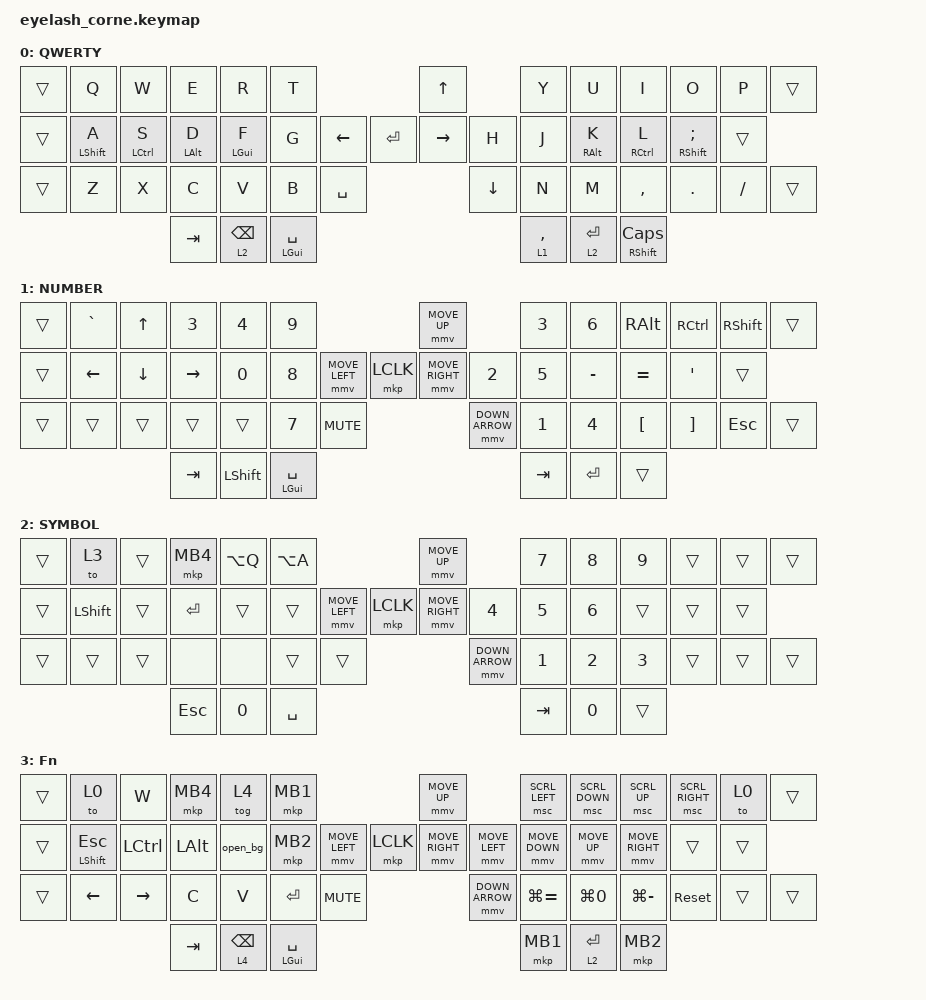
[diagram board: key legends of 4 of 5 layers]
// Copyright (c) 2022 The ZMK Contributors
// SPDX-License-Identifier: MIT

#define ZMK_POINTING_DEFAULT_MOVE_VAL 2500
#define ZMK_POINTING_DEFAULT_SCRL_VAL 20

#include <input/processors.dtsi>
#include <zephyr/dt-bindings/input/input-event-codes.h>
#include <behaviors.dtsi>
#include <dt-bindings/zmk/keys.h>
#include <dt-bindings/zmk/pointing.h>
#include <dt-bindings/zmk/rgb.h>

/* 挂载到 &mmv_input_listener：在 4 号图层激活时强制将 XY 位移转化为滚轮信号 */
&mmv_input_listener {
    input-processors = <&zip_xy_scaler 1 1>;

    scroll_mode {
        layers = <4>;
        input-processors = <&zip_xy_to_scroll_mapper>, <&zip_scroll_scaler 1 1>;
    };
};

&msc_input_listener { input-processors = <&zip_scroll_scaler 1 1>; };

&msc {
    acceleration-exponent = <0>;
    time-to-max-speed-ms = <0>;
    delay-ms = <0>;
};

&mmv {
    acceleration-exponent = <1>;
    time-to-max-speed-ms = <200>;
    delay-ms = <0>;
};

&soft_off { hold-time-ms = <2000>; };

/ {
    macros {
        open_bg: open_bg {
            compatible = "zmk,behavior-macro";
            #binding-cells = <0>;
            bindings =
                <&macro_press>,
                <&kp LGUI>,
                <&macro_tap>,
                <&mkp LCLK>,
                <&macro_release>,
                <&kp LGUI>;
        };
    };

    behaviors {
        td0: td0 {
            compatible = "zmk,behavior-tap-dance";
            display-name = "Shift/Caps Lock Tap Dance";
            #binding-cells = <0>;
            bindings = <&kp LEFT_SHIFT>, <&kp CAPS>;
        };

        hm: homerow_mods {
            compatible = "zmk,behavior-hold-tap";
            #binding-cells = <2>;
            tapping-term-ms = <200>;
            quick-tap-ms = <175>;
            require-prior-idle-ms = <150>;
            flavor = "balanced";
            bindings = <&kp>, <&kp>;
        };
    };

    rgb_encoder: rgb_encoder {
        compatible = "zmk,behavior-sensor-rotate";
        #sensor-binding-cells = <0>;
        bindings = <&rgb_ug RGB_BRI>, <&rgb_ug RGB_BRD>;
    };

    scroll_encoder: scroll_encoder {
        compatible = "zmk,behavior-sensor-rotate";
        #sensor-binding-cells = <0>;
        bindings = <&msc SCRL_DOWN>, <&msc SCRL_UP>;

        tap-ms = <20>;
    };

    combos {
        compatible = "zmk,combos";

        rt {
            bindings = <&kp LEFT_PARENTHESIS>;
            key-positions = <4 5>;
        };

        yu {
            bindings = <&kp RIGHT_PARENTHESIS>;
            key-positions = <7 8>;
        };

        vb {
            bindings = <&kp LS(APOSTROPHE)>;
            key-positions = <32 33>;
        };

        nm {
            bindings = <&kp APOSTROPHE>;
            key-positions = <36 37>;
        };

        qw {
            bindings = <&kp ESC>;
            key-positions = <1 2>;
        };
    };

    keymap {
        compatible = "zmk,keymap";

        default_layer {
            display-name = "QWERTY";
            bindings = <
&trans  &kp Q              &kp W               &kp E               &kp R            &kp T                                                          &kp UP                &kp Y        &kp U        &kp I                 &kp O                &kp P                      &trans
&trans  &hm LEFT_SHIFT A  &hm LEFT_CONTROL S  &hm LEFT_ALT D      &hm LEFT_GUI F   &kp G                                               &kp LEFT  &kp ENTER  &kp RIGHT  &kp H        &kp J        &hm RIGHT_ALT K       &hm RIGHT_CONTROL L  &hm RIGHT_SHIFT SEMICOLON  &trans
&trans  &kp Z              &kp X               &kp C               &kp V            &kp B               &kp SPACE                      &kp DOWN               &kp N        &kp M        &kp COMMA             &kp DOT              &kp FSLH                   &trans
                                               &kp TAB             &lt 2 BACKSPACE  &mt LEFT_GUI SPACE                                                                    &lt 1 COMMA  &lt 2 ENTER  &mt RIGHT_SHIFT CAPS
            >;

            sensor-bindings = <&inc_dec_kp C_VOLUME_UP C_VOL_DN>;
        };

        lower_layer {
            display-name = "NUMBER";
            bindings = <
&trans  &kp GRAVE       &kp UP_ARROW    &kp N3           &kp N4          &kp N9                                                             &mmv MOVE_UP                      &kp NUMBER_3  &kp NUMBER_6  &kp RIGHT_ALT  &kp RIGHT_CONTROL  &kp RSHIFT  &trans
&trans  &kp LEFT_ARROW  &kp DOWN_ARROW  &kp RIGHT_ARROW  &kp NUMBER_0    &kp NUMBER_8                      &mmv MOVE_LEFT  &mkp LCLK        &mmv MOVE_RIGHT  &kp NUMBER_2  &kp N5        &kp MINUS      &kp EQUAL          &kp SQT     &trans
&trans  &trans          &trans          &trans           &trans          &kp N7       &kp C_MUTE                                            &mmv DOWN_ARROW                   &kp NUMBER_1  &kp NUMBER_4  &kp LBKT       &kp RBKT           &kp ESC     &trans
                                        &kp TAB          &kp LEFT_SHIFT  &mt LEFT_GUI SPACE                                                                                 &kp TAB       &kp ENTER     &trans
            >;

            sensor-bindings = <&scroll_encoder>;
        };

        raise_layer {
            display-name = "SYMBOL";
            bindings = <
&trans  &to 3           &trans  &mkp MB4   &kp LA(Q)     &kp LA(A)                            &mmv MOVE_UP                     &kp NUMBER_7  &kp NUMBER_8  &kp NUMBER_9  &trans  &trans  &trans
&trans  &kp LEFT_SHIFT  &trans  &kp ENTER  &trans        &trans               &mmv MOVE_LEFT  &mkp LCLK        &mmv MOVE_RIGHT &kp NUMBER_4  &kp NUMBER_5  &kp NUMBER_6  &trans  &trans  &trans
&trans  &trans          &trans  &none      &none         &trans     &trans                                     &mmv DOWN_ARROW                  &kp NUMBER_1  &kp NUMBER_2  &kp NUMBER_3  &trans  &trans  &trans
                                &kp ESC    &kp NUMBER_0  &kp SPACE                                                                             &kp TAB       &kp NUMBER_0  &trans
            >;

            sensor-bindings = <&scroll_encoder>;
        };

        layer_3 {
            display-name = "Fn";
            bindings = <
&trans  &to 0               &kp W             &mkp MB4      &tog 4           &mkp MB1                                                          &mmv MOVE_UP                      &msc SCRL_LEFT  &msc SCRL_DOWN    &msc SCRL_UP   &msc SCRL_RIGHT  &to 0   &trans
&trans  &mt LEFT_SHIFT ESC  &kp LEFT_CONTROL  &kp LEFT_ALT  &open_bg         &mkp MB2                          &mmv MOVE_LEFT  &mkp LCLK       &mmv MOVE_RIGHT  &mmv MOVE_LEFT  &mmv MOVE_DOWN  &mmv MOVE_UP      &mmv MOVE_RIGHT &trans  &trans
&trans  &kp LEFT_ARROW      &kp RIGHT_ARROW   &kp C         &kp V            &kp ENTER   &kp C_MUTE                                            &mmv DOWN_ARROW                   &kp LG(EQUAL)   &kp LG(NUMBER_0)  &kp LG(MINUS)  &sys_reset       &trans  &trans
                                              &kp TAB       &lt 4 BACKSPACE  &mt LEFT_GUI SPACE                                                                                 &mkp MB1        &lt 2 ENTER       &mkp MB2
            >;

            sensor-bindings = <&scroll_encoder>;
        };

        mouse_lock_layer {
            display-name = "SCROLL";
            bindings = <
&trans  &kp NUMBER_1  &kp NUMBER_2  &kp NUMBER_3  &tog 4    &kp LA(A)                    &trans          &trans     &trans  &trans  &trans  &trans  &trans
&trans  &trans        &trans        &trans        &trans    &trans               &trans  &trans  &trans  &trans     &trans  &trans  &trans  &trans  &trans
&trans  &trans        &trans        &trans        &trans    &trans     &trans                    &trans             &trans  &trans  &trans  &trans  &trans
                                    &trans        &trans    &trans                                                  &kp SPACE  &trans  &trans
            >;

            sensor-bindings = <&scroll_encoder>;
        };
    };
};
